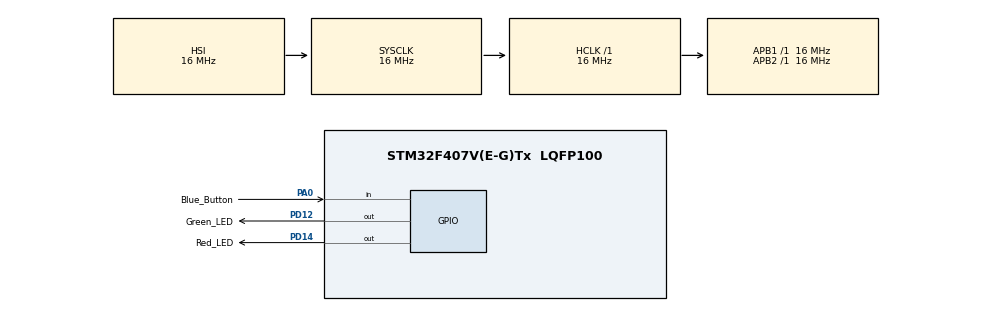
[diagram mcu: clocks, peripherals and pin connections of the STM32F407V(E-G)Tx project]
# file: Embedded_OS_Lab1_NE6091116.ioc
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Mcu.Family=STM32F4
Mcu.Name=STM32F407V(E-G)Tx
Mcu.Package=LQFP100
NVIC.PriorityGroup=NVIC_PRIORITYGROUP_4
NVIC.TIM6_DAC_IRQn=true\:0\:0\:false\:false\:true\:false\:true
NVIC.TimeBase=TIM6_DAC_IRQn
NVIC.TimeBaseIP=TIM6
PA0-WKUP.GPIO_Label=Blue_Button
PA0-WKUP.Signal=GPIO_Input
PA13.Mode=Serial_Wire
PA13.Signal=SYS_JTMS-SWDIO
PA14.Mode=Serial_Wire
PA14.Signal=SYS_JTCK-SWCLK
PD12.GPIO_Label=Green_LED
PD12.Signal=GPIO_Output
PD14.GPIO_Label=Red_LED
PD14.Signal=GPIO_Output
ProjectManager.HeapSize=0x200
ProjectManager.StackSize=0x400
ProjectManager.TargetToolchain=STM32CubeIDE
RCC.AHBFreq_Value=16000000
RCC.APB1Freq_Value=16000000
RCC.APB2Freq_Value=16000000
RCC.CortexFreq_Value=16000000
RCC.HSE_VALUE=25000000
RCC.HSI_VALUE=16000000
RCC.LSE_VALUE=32768
RCC.SYSCLKFreq_VALUE=16000000
RCC.VCOOutputFreq_Value=192000000
VP_SYS_VS_tim6.Mode=TIM6
board=custom

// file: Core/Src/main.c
/* USER CODE BEGIN Header */
/**
  ******************************************************************************
  * @file           : main.c
  * @brief          : Main program body
  ******************************************************************************
  * @attention
  *
  * <h2><center>&copy; Copyright (c) 2021 STMicroelectronics.
  * All rights reserved.</center></h2>
  *
  * This software component is licensed by ST under BSD 3-Clause license,
  * the "License"; You may not use this file except in compliance with the
  * License. You may obtain a copy of the License at:
  *                        opensource.org/licenses/BSD-3-Clause
  *
  ******************************************************************************
  */
/* USER CODE END Header */
#include "main.h"

/* USER CODE BEGIN Includes */
#include "FreeRTOS.h"
#include "task.h"
#include "queue.h"
/* USER CODE END Includes */

void SystemClock_Config(void);
static void MX_GPIO_Init(void);
void LED_Task(void);
void Button_Task(void);

/* USER CODE BEGIN 0 */
QueueHandle_t xQueue;

/* USER CODE END 0 */

int main(void)
{
  /* USER CODE BEGIN 1 */
	xQueue = xQueueCreate(10, sizeof(int));
  /* USER CODE END 1 */

  /* MCU Configuration--------------------------------------------------------*/

  /* Reset of all peripherals, Initializes the Flash interface and the Systick. */
  HAL_Init();

  /* Configure the system clock */
  SystemClock_Config();

  /* Initialize all configured peripherals */
  MX_GPIO_Init();
  /* USER CODE BEGIN 2 */
  xTaskCreate(
                      LED_Task,       /* Function that implements the task. */
                      "NAME",          /* Text name for the task. */
                      130,      /* Stack size in words, not bytes. */
                      NULL,
                      0,
                      NULL);
  xTaskCreate(
                       Button_Task,       /* Function that implements the task. */
                       "NAME",          /* Text name for the task. */
                       130,      /* Stack size in words, not bytes. */
                       NULL,
                       0,
                       NULL);
  vTaskStartScheduler();
  /* USER CODE END 2 */

  /* Infinite loop */
  while (1)
  {

  }
}

void SystemClock_Config(void)
{
  RCC_OscInitTypeDef RCC_OscInitStruct = {0};
  RCC_ClkInitTypeDef RCC_ClkInitStruct = {0};

  /** Configure the main internal regulator output voltage
  */
  __HAL_RCC_PWR_CLK_ENABLE();
  __HAL_PWR_VOLTAGESCALING_CONFIG(PWR_REGULATOR_VOLTAGE_SCALE1);
  /** Initializes the RCC Oscillators according to the specified parameters
  * in the RCC_OscInitTypeDef structure.
  */
  RCC_OscInitStruct.OscillatorType = RCC_OSCILLATORTYPE_HSI;
  RCC_OscInitStruct.HSIState = RCC_HSI_ON;
  RCC_OscInitStruct.HSICalibrationValue = RCC_HSICALIBRATION_DEFAULT;
  RCC_OscInitStruct.PLL.PLLState = RCC_PLL_NONE;
  if (HAL_RCC_OscConfig(&RCC_OscInitStruct) != HAL_OK)
  {
    Error_Handler();
  }
  /** Initializes the CPU, AHB and APB buses clocks
  */
  RCC_ClkInitStruct.ClockType = RCC_CLOCKTYPE_HCLK|RCC_CLOCKTYPE_SYSCLK
                              |RCC_CLOCKTYPE_PCLK1|RCC_CLOCKTYPE_PCLK2;
  RCC_ClkInitStruct.SYSCLKSource = RCC_SYSCLKSOURCE_HSI;
  RCC_ClkInitStruct.AHBCLKDivider = RCC_SYSCLK_DIV1;
  RCC_ClkInitStruct.APB1CLKDivider = RCC_HCLK_DIV1;
  RCC_ClkInitStruct.APB2CLKDivider = RCC_HCLK_DIV1;

  if (HAL_RCC_ClockConfig(&RCC_ClkInitStruct, FLASH_LATENCY_0) != HAL_OK)
  {
    Error_Handler();
  }
}

static void MX_GPIO_Init(void)
{
  GPIO_InitTypeDef GPIO_InitStruct = {0};

  /* GPIO Ports Clock Enable */
  __HAL_RCC_GPIOA_CLK_ENABLE();
  __HAL_RCC_GPIOD_CLK_ENABLE();

  /*Configure GPIO pin Output Level */
  HAL_GPIO_WritePin(GPIOD, Green_LED_Pin|Red_LED_Pin, GPIO_PIN_RESET);

  /*Configure GPIO pin : Blue_Button_Pin */
  GPIO_InitStruct.Pin = Blue_Button_Pin;
  GPIO_InitStruct.Mode = GPIO_MODE_INPUT;
  GPIO_InitStruct.Pull = GPIO_NOPULL;
  HAL_GPIO_Init(Blue_Button_GPIO_Port, &GPIO_InitStruct);

  /*Configure GPIO pins : Green_LED_Pin Red_LED_Pin */
  GPIO_InitStruct.Pin = Green_LED_Pin|Red_LED_Pin;
  GPIO_InitStruct.Mode = GPIO_MODE_OUTPUT_PP;
  GPIO_InitStruct.Pull = GPIO_NOPULL;
  GPIO_InitStruct.Speed = GPIO_SPEED_FREQ_LOW;
  HAL_GPIO_Init(GPIOD, &GPIO_InitStruct);

}

/* USER CODE BEGIN 4 */
void LED_Task (){
	int xrxdata = 0;//receive parameter
	int mode = 1;//兩種模式轉換
	for(;;){
		if (xQueueReceive(xQueue, &xrxdata, 0)){
			//Button already pressed,LED mode will be changed
			mode = (mode+1)%2;

			for(;;){
				//mode 0 :green <-> red
				if(mode == 0){
					HAL_GPIO_WritePin(Green_LED_GPIO_Port, GPIO_PIN_12, GPIO_PIN_SET);
					if(xQueueReceive(xQueue, &xrxdata, 5000)){//容忍5000毫秒
						mode = (mode+1)%2;
					HAL_GPIO_WritePin(Green_LED_GPIO_Port, GPIO_PIN_12, GPIO_PIN_RESET);///
						continue;
					}
					HAL_GPIO_WritePin(Green_LED_GPIO_Port, GPIO_PIN_12, GPIO_PIN_RESET);
					if(xQueueReceive(xQueue, &xrxdata, 0)){
						mode = (mode+1)%2;
						continue;
					}
					HAL_GPIO_WritePin(Red_LED_GPIO_Port, GPIO_PIN_14, GPIO_PIN_SET);
					if(xQueueReceive(xQueue, &xrxdata, 5000)){
						mode = (mode+1)%2;
					HAL_GPIO_WritePin(Red_LED_GPIO_Port, GPIO_PIN_14, GPIO_PIN_RESET);
						continue;
					}
					HAL_GPIO_WritePin(Red_LED_GPIO_Port, GPIO_PIN_14, GPIO_PIN_RESET);///
					if(xQueueReceive(xQueue, &xrxdata, 0)){
						mode =(mode+1)%2;
						continue;
					}
				}

			else if(mode==1){
					//HAL_GPIO_WritePin(Green_LED_GPIO_Port, GPIO_PIN_12, GPIO_PIN_RESET);
					// if(xQueueReceive(xQueue, &xrxdata,0)){
					// 	mode = (mode+1)%2;
					// }
					HAL_GPIO_WritePin(Red_LED_GPIO_Port, GPIO_PIN_14, GPIO_PIN_SET);
					if(xQueueReceive(xQueue, &xrxdata, 1000)){
						mode = (mode+1)%2;
					HAL_GPIO_WritePin(Red_LED_GPIO_Port, GPIO_PIN_14, GPIO_PIN_RESET);//
						continue;
					}
					HAL_GPIO_WritePin(Red_LED_GPIO_Port, GPIO_PIN_14, GPIO_PIN_RESET);
					if(xQueueReceive(xQueue, &xrxdata, 1000)){
						mode = (mode+1)%2;
						continue;
					}
				}
		}
	}
}
}

void Button_Task(){
		int xtxdata = 0;
		GPIO_PinState prevState = GPIO_PIN_RESET;
		GPIO_PinState curState = GPIO_PIN_RESET;

		for(;;){
			curState = HAL_GPIO_ReadPin(Blue_Button_GPIO_Port,GPIO_PIN_0);
			if(curState != prevState) {
				if (curState == GPIO_PIN_SET) {
	    			prevState = GPIO_PIN_SET;
	    			xQueueSend( xQueue,
	                            &xtxdata,
	                            0
	                            );
				}
				else if(curState == GPIO_PIN_RESET){
				    prevState = GPIO_PIN_RESET;
				}
	        }
	        vTaskDelay(35);
	    }
	}

/* USER CODE END 4 */

 /**
  * @brief  Period elapsed callback in non blocking mode
  * @note   This function is called  when TIM6 interrupt took place, inside
  * HAL_TIM_IRQHandler(). It makes a direct call to HAL_IncTick() to increment
  * a global variable "uwTick" used as application time base.
  * @param  htim : TIM handle
  * @retval None
  */
void HAL_TIM_PeriodElapsedCallback(TIM_HandleTypeDef *htim)
{
  if (htim->Instance == TIM6) {
    HAL_IncTick();
  }
}

void Error_Handler(void)
{
  __disable_irq();
  while (1)
  {
  }
}

  USE_FULL_ASSERT
/**
  * @brief  Reports the name of the source file and the source line number
  *         where the assert_param error has occurred.
  * @param  file: pointer to the source file name
  * @param  line: assert_param error line source number
  * @retval None
  */
void assert_failed(uint8_t *file, uint32_t line)
{
}
#endif /* USE_FULL_ASSERT */

/************************ (C) COPYRIGHT STMicroelectronics *****END OF FILE****/
